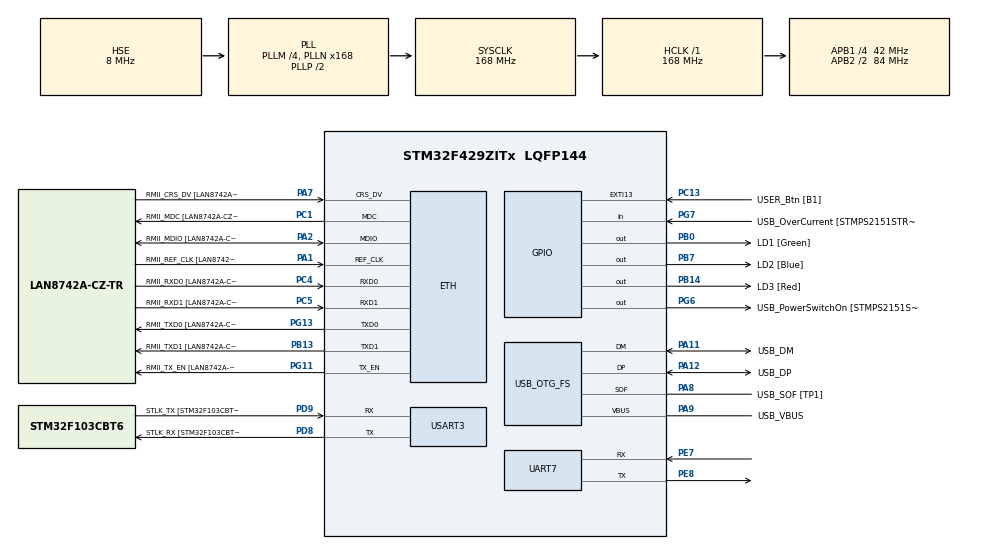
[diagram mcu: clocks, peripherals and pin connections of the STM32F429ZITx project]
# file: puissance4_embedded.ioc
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Mcu.Family=STM32F4
FREERTOS.Queues01=queue_user_to_app,16,data_msg,0,Dynamic,NULL,NULL;queue_app_to_display,16,data_msg,0,Dynamic,NULL,NULL
RCC.CortexFreq_Value=168000000
PG6.Signal=GPIO_Output
PB14.GPIO_Label=LD3 [Red]
PG6.GPIO_Label=USB_PowerSwitchOn [STMPS2151STR_EN]
PA14.GPIO_Label=TCK
RCC.SYSCLKSourceVirtual=RCC_SYSCLKSOURCE_PLLCLK
PA11.Mode=Device_Only
PB0.GPIO_Label=LD1 [Green]
PC14/OSC32_IN.Mode=LSE-External-Oscillator
PC5.Mode=RMII
PC13.GPIO_Label=USER_Btn [B1]
PB13.GPIO_Label=RMII_TXD1 [LAN8742A-CZ-TR_TXD1]
PB13.Signal=ETH_TXD1
PG13.Signal=ETH_TXD0
PD9.Mode=Asynchronous
PG11.Signal=ETH_TX_EN
RCC.SYSCLKSource=RCC_SYSCLKSOURCE_PLLCLK
ProjectManager.StackSize=0x400
VP_FREERTOS_VS_CMSIS_V2.Mode=CMSIS_V2
PA12.Signal=USB_OTG_FS_DP
ETH.PHY_Value=0
PH0/OSC_IN.Mode=HSE-External-Clock-Source
RCC.HCLKFreq_Value=168000000
RCC.APB2TimFreq_Value=168000000
PH1/OSC_OUT.Signal=RCC_OSC_OUT
PD8.Signal=USART3_TX
RCC.AHBFreq_Value=168000000
RCC.HSE_VALUE=8000000
RCC.PLLMUL=RCC_PLL_MUL9
PC4.GPIO_Label=RMII_RXD0 [LAN8742A-CZ-TR_RXD0]
PA14.Mode=Serial_Wire
VP_SYS_VS_tim1.Mode=TIM1
PA10.GPIO_Label=USB_ID
PB7.Signal=GPIO_Output
PA8.Signal=USB_OTG_FS_SOF
PG13.Mode=RMII
ETH.PHY_Name=LAN8742A_PHY_ADDRESS
PH1/OSC_OUT.Mode=HSE-External-Clock-Source
PB7.GPIO_Label=LD2 [Blue]
Mcu.Package=LQFP144
NVIC.TimeBase=TIM1_UP_TIM10_IRQn
PC14/OSC32_IN.Signal=RCC_OSC32_IN
PA2.GPIO_Label=RMII_MDIO [LAN8742A-CZ-TR_MDIO]
NVIC.TimeBaseIP=TIM1
PA10.Signal=USB_OTG_FS_ID
USB_OTG_FS.VirtualMode=Device_Only
RCC.APB2CLKDivider=RCC_HCLK_DIV2
RCC.APB1TimFreq_Value=84000000
PG11.GPIO_Label=RMII_TX_EN [LAN8742A-CZ-TR_TXEN]
PC5.Signal=ETH_RXD1
PB13.Mode=RMII
PE7.Signal=UART7_RX
PC4.Mode=RMII
FREERTOS.Tasks01=user_command,24,128,user_button,As weak,NULL,Dynamic,NULL,NULL;app_puissance4,24,128,application,As external,NULL,Dynamic,NULL,NULL;display_board,24,128,show_board,As external,NULL,Dynamic,NULL,NULL;task_timer,24,128,timers,As external,NULL,Dynamic,NULL,NULL;task_serial,24,128,serial,As external,NULL,Dynamic,NULL,NULL
PA7.Mode=RMII
PG7.Signal=GPIO_Input
PD9.GPIO_Label=STLK_TX [STM32F103CBT6_PA2]
PC13.Signal=GPXTI13
PA9.GPIO_Label=USB_VBUS
PC4.Signal=ETH_RXD0
PA11.GPIO_Label=USB_DM
PD9.Signal=USART3_RX
UART7.VirtualMode=Asynchronous
RCC.APB1CLKDivider=RCC_HCLK_DIV4
PG13.GPIO_Label=RMII_TXD0 [LAN8742A-CZ-TR_TXD0]
ETH.PhyAddress=0
PA12.GPIO_Label=USB_DP
PD8.GPIO_Label=STLK_RX [STM32F103CBT6_PA3]
PE8.Mode=Asynchronous
PA13.Signal=SYS_JTMS-SWDIO
PA9.Mode=Activate_VBUS
PA8.GPIO_Label=USB_SOF [TP1]
ProjectManager.TargetToolchain=TrueSTUDIO
PA9.Signal=USB_OTG_FS_VBUS
RCC.USBFreq_Value=48000000
PD8.Mode=Asynchronous
PA1.Signal=ETH_REF_CLK
PB14.Signal=GPIO_Output
board=NUCLEO-F429ZI
RCC.VCOOutputFreq_Value=336000000
PH0/OSC_IN.Signal=RCC_OSC_IN
RCC.APB2Freq_Value=84000000
PA1.Mode=RMII
RCC.PRESCALERUSB=RCC_USBCLKSOURCE_PLL_DIV1_5
PE8.Signal=UART7_TX
PG7.GPIO_Label=USB_OverCurrent [STMPS2151STR_FAULT]
PA1.GPIO_Label=RMII_REF_CLK [LAN8742A-CZ-TR_REFCLK0]
PC1.GPIO_Label=RMII_MDC [LAN8742A-CZ-TR_MDC]
PA13.Mode=Serial_Wire
Mcu.Name=STM32F429ZITx
PA2.Signal=ETH_MDIO
PA13.GPIO_Label=TMS
RCC.APB2TimCLKDivider=2
RCC.48MHZClocksFreq_Value=48000000
RCC.SYSCLKFreq_VALUE=168000000
PE7.Mode=Asynchronous
ETH.MediaInterface=ETH_MEDIA_INTERFACE_RMII
PA7.GPIO_Label=RMII_CRS_DV [LAN8742A-CZ-TR_CRS_DV]
PA12.Mode=Device_Only
PC5.GPIO_Label=RMII_RXD1 [LAN8742A-CZ-TR_RXD1]
USART3.VirtualMode=VM_ASYNC
PC15/OSC32_OUT.Mode=LSE-External-Oscillator
PG11.Mode=RMII
PA11.Signal=USB_OTG_FS_DM
PA14.Signal=SYS_JTCK-SWCLK
ProjectManager.HeapSize=0x200
NVIC.TIM1_UP_TIM10_IRQn=true\:0\:0\:false\:false\:true\:false\:false\:true
RCC.HSI_VALUE=16000000
PH0/OSC_IN.GPIO_Label=MCO [STM32F103CBT6_PA8]
FREERTOS.Mutexes01=timer_mutex,Dynamic,NULL
RCC.PLLQ=7
NVIC.PriorityGroup=NVIC_PRIORITYGROUP_4
RCC.PLLM=4
RCC.PLLN=168
PA2.Mode=RMII
PC15/OSC32_OUT.Signal=RCC_OSC32_OUT
PA8.Mode=Activate_SOF_FS
RCC.APB1Freq_Value=42000000
PB0.Signal=GPIO_Output
PC1.Signal=ETH_MDC
PC1.Mode=RMII
PA7.Signal=ETH_CRS_DV

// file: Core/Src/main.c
/* USER CODE BEGIN Header */
/**
 ******************************************************************************
 * @file           : main.c
 * @brief          : Main program body
 ******************************************************************************
 * @attention
 *
 * <h2><center>&copy; Copyright (c) 2020 STMicroelectronics.
 * All rights reserved.</center></h2>
 *
 * This software component is licensed by ST under Ultimate Liberty license
 * SLA0044, the "License"; You may not use this file except in compliance with
 * the License. You may obtain a copy of the License at:
 *                             www.st.com/SLA0044
 *
 ******************************************************************************
 */
/* USER CODE END Header */
#include "main.h"
#include "cmsis_os.h"

/* USER CODE BEGIN Includes */
#include "game.h"
#include "leds_control.h"
/* USER CODE END Includes */

ETH_HandleTypeDef heth;

UART_HandleTypeDef huart7;
UART_HandleTypeDef huart3;

PCD_HandleTypeDef hpcd_USB_OTG_FS;

/* Definitions for user_command */
osThreadId_t user_commandHandle;
const osThreadAttr_t user_command_attributes = {
  .name = "user_command",
  .priority = (osPriority_t) osPriorityNormal,
  .stack_size = 128 * 4
};
/* Definitions for app_puissance4 */
osThreadId_t app_puissance4Handle;
const osThreadAttr_t app_puissance4_attributes = {
  .name = "app_puissance4",
  .priority = (osPriority_t) osPriorityNormal,
  .stack_size = 128 * 4
};
/* Definitions for display_board */
osThreadId_t display_boardHandle;
const osThreadAttr_t display_board_attributes = {
  .name = "display_board",
  .priority = (osPriority_t) osPriorityNormal,
  .stack_size = 128 * 4
};
/* Definitions for task_timer */
osThreadId_t task_timerHandle;
const osThreadAttr_t task_timer_attributes = {
  .name = "task_timer",
  .priority = (osPriority_t) osPriorityNormal,
  .stack_size = 128 * 4
};
/* Definitions for task_serial */
osThreadId_t task_serialHandle;
const osThreadAttr_t task_serial_attributes = {
  .name = "task_serial",
  .priority = (osPriority_t) osPriorityNormal,
  .stack_size = 128 * 4
};
/* Definitions for queue_user_to_app */
osMessageQueueId_t queue_user_to_appHandle;
const osMessageQueueAttr_t queue_user_to_app_attributes = {
  .name = "queue_user_to_app"
};
/* Definitions for queue_app_to_display */
osMessageQueueId_t queue_app_to_displayHandle;
const osMessageQueueAttr_t queue_app_to_display_attributes = {
  .name = "queue_app_to_display"
};
/* Definitions for timer_mutex */
//osMutexId_t timer_mutexHandle;
//const osMutexAttr_t timer_mutex_attributes = {
//  .name = "timer_mutex"
//};
/* USER CODE BEGIN PV */
/* Definitions for queue_huart_transmit */
osMessageQueueId_t queue_huart_transmitHandle;
const osMessageQueueAttr_t queue_huart_transmit_attributes = {
		.name = "queue_user_transmit"
};
/* Definitions for queue_huart_receive */
osMessageQueueId_t queue_huart_receiveHandle;
const osMessageQueueAttr_t queue_huart_receive_attributes = {
		.name = "queue_huart_receive"
};
/* USER CODE END PV */

void SystemClock_Config(void);
static void MX_GPIO_Init(void);
static void MX_ETH_Init(void);
static void MX_USART3_UART_Init(void);
static void MX_USB_OTG_FS_PCD_Init(void);
static void MX_UART7_Init(void);
void user_button(void *argument);
extern void application(void *argument);
extern void show_board(void *argument);
extern void timers(void *argument);
extern void serial(void *argument);

int main(void)
{

  /* MCU Configuration--------------------------------------------------------*/

  /* Reset of all peripherals, Initializes the Flash interface and the Systick. */
  HAL_Init();

  /* Configure the system clock */
  SystemClock_Config();

  /* Initialize all configured peripherals */
  MX_GPIO_Init();
  //MX_ETH_Init();
  MX_USART3_UART_Init();
  //MX_USB_OTG_FS_PCD_Init();
  MX_UART7_Init();

  /* Init scheduler */
  osKernelInitialize();
  /* Create the mutex(es) */
  /* creation of timer_mutex */
  //timer_mutexHandle = osMutexNew(&timer_mutex_attributes);

  /* Create the queue(s) */
  /* creation of queue_user_to_app */
  queue_user_to_appHandle = osMessageQueueNew (16, sizeof(data_msg), &queue_user_to_app_attributes);

  /* creation of queue_app_to_display */
  queue_app_to_displayHandle = osMessageQueueNew (16, sizeof(data_msg), &queue_app_to_display_attributes);

  /* USER CODE BEGIN RTOS_QUEUES */
	/* creation of queue_huart_transmit */
	queue_huart_transmitHandle = osMessageQueueNew (16, SIZE_OF_LED_COMMAND_BUFFER, &queue_huart_transmit_attributes);

	/* creation of queue_huart_receive */
	queue_huart_receiveHandle = osMessageQueueNew (16, SIZE_OF_PLAYER_COMMAND_BUFFER, &queue_huart_receive_attributes);
  /* USER CODE END RTOS_QUEUES */

  /* Create the thread(s) */
  /* creation of user_command */
  user_commandHandle = osThreadNew(user_button, NULL, &user_command_attributes);

  /* creation of app_puissance4 */
  app_puissance4Handle = osThreadNew(application, NULL, &app_puissance4_attributes);

  /* creation of display_board */
  display_boardHandle = osThreadNew(show_board, NULL, &display_board_attributes);

  /* creation of task_timer */
  task_timerHandle = osThreadNew(timers, NULL, &task_timer_attributes);

  /* creation of task_serial */
  task_serialHandle = osThreadNew(serial, NULL, &task_serial_attributes);

  /* Start scheduler */
  osKernelStart();

  /* We should never get here as control is now taken by the scheduler */
  /* Infinite loop */
	while (1)
	{

	}
}

void SystemClock_Config(void)
{
  RCC_OscInitTypeDef RCC_OscInitStruct = {0};
  RCC_ClkInitTypeDef RCC_ClkInitStruct = {0};

  /** Configure the main internal regulator output voltage
  */
  __HAL_RCC_PWR_CLK_ENABLE();
  __HAL_PWR_VOLTAGESCALING_CONFIG(PWR_REGULATOR_VOLTAGE_SCALE1);
  /** Initializes the RCC Oscillators according to the specified parameters
  * in the RCC_OscInitTypeDef structure.
  */
  RCC_OscInitStruct.OscillatorType = RCC_OSCILLATORTYPE_HSE;
  RCC_OscInitStruct.HSEState = RCC_HSE_BYPASS;
  RCC_OscInitStruct.PLL.PLLState = RCC_PLL_ON;
  RCC_OscInitStruct.PLL.PLLSource = RCC_PLLSOURCE_HSE;
  RCC_OscInitStruct.PLL.PLLM = 4;
  RCC_OscInitStruct.PLL.PLLN = 168;
  RCC_OscInitStruct.PLL.PLLP = RCC_PLLP_DIV2;
  RCC_OscInitStruct.PLL.PLLQ = 7;
  if (HAL_RCC_OscConfig(&RCC_OscInitStruct) != HAL_OK)
  {
    Error_Handler();
  }
  /** Initializes the CPU, AHB and APB buses clocks
  */
  RCC_ClkInitStruct.ClockType = RCC_CLOCKTYPE_HCLK|RCC_CLOCKTYPE_SYSCLK
                              |RCC_CLOCKTYPE_PCLK1|RCC_CLOCKTYPE_PCLK2;
  RCC_ClkInitStruct.SYSCLKSource = RCC_SYSCLKSOURCE_PLLCLK;
  RCC_ClkInitStruct.AHBCLKDivider = RCC_SYSCLK_DIV1;
  RCC_ClkInitStruct.APB1CLKDivider = RCC_HCLK_DIV4;
  RCC_ClkInitStruct.APB2CLKDivider = RCC_HCLK_DIV2;

  if (HAL_RCC_ClockConfig(&RCC_ClkInitStruct, FLASH_LATENCY_5) != HAL_OK)
  {
    Error_Handler();
  }
}

static void MX_ETH_Init(void)
{

  heth.Instance = ETH;
  heth.Init.AutoNegotiation = ETH_AUTONEGOTIATION_ENABLE;
  heth.Init.PhyAddress = LAN8742A_PHY_ADDRESS;
  heth.Init.MACAddr[0] =   0x00;
  heth.Init.MACAddr[1] =   0x80;
  heth.Init.MACAddr[2] =   0xE1;
  heth.Init.MACAddr[3] =   0x00;
  heth.Init.MACAddr[4] =   0x00;
  heth.Init.MACAddr[5] =   0x00;
  heth.Init.RxMode = ETH_RXPOLLING_MODE;
  heth.Init.ChecksumMode = ETH_CHECKSUM_BY_HARDWARE;
  heth.Init.MediaInterface = ETH_MEDIA_INTERFACE_RMII;

  if (HAL_ETH_Init(&heth) != HAL_OK)
  {
    Error_Handler();
  }

}

static void MX_UART7_Init(void)
{

  huart7.Instance = UART7;
  huart7.Init.BaudRate = 115200;
  huart7.Init.WordLength = UART_WORDLENGTH_8B;
  huart7.Init.StopBits = UART_STOPBITS_1;
  huart7.Init.Parity = UART_PARITY_NONE;
  huart7.Init.Mode = UART_MODE_TX_RX;
  huart7.Init.HwFlowCtl = UART_HWCONTROL_NONE;
  huart7.Init.OverSampling = UART_OVERSAMPLING_16;
  if (HAL_UART_Init(&huart7) != HAL_OK)
  {
    Error_Handler();
  }

}

static void MX_USART3_UART_Init(void)
{

  huart3.Instance = USART3;
  huart3.Init.BaudRate = 115200;
  huart3.Init.WordLength = UART_WORDLENGTH_8B;
  huart3.Init.StopBits = UART_STOPBITS_1;
  huart3.Init.Parity = UART_PARITY_NONE;
  huart3.Init.Mode = UART_MODE_TX_RX;
  huart3.Init.HwFlowCtl = UART_HWCONTROL_NONE;
  huart3.Init.OverSampling = UART_OVERSAMPLING_16;
  if (HAL_UART_Init(&huart3) != HAL_OK)
  {
    Error_Handler();
  }

}

static void MX_USB_OTG_FS_PCD_Init(void)
{

  hpcd_USB_OTG_FS.Instance = USB_OTG_FS;
  hpcd_USB_OTG_FS.Init.dev_endpoints = 4;
  hpcd_USB_OTG_FS.Init.speed = PCD_SPEED_FULL;
  hpcd_USB_OTG_FS.Init.dma_enable = DISABLE;
  hpcd_USB_OTG_FS.Init.phy_itface = PCD_PHY_EMBEDDED;
  hpcd_USB_OTG_FS.Init.Sof_enable = ENABLE;
  hpcd_USB_OTG_FS.Init.low_power_enable = DISABLE;
  hpcd_USB_OTG_FS.Init.lpm_enable = DISABLE;
  hpcd_USB_OTG_FS.Init.vbus_sensing_enable = ENABLE;
  hpcd_USB_OTG_FS.Init.use_dedicated_ep1 = DISABLE;
  if (HAL_PCD_Init(&hpcd_USB_OTG_FS) != HAL_OK)
  {
    Error_Handler();
  }

}

static void MX_GPIO_Init(void)
{
  GPIO_InitTypeDef GPIO_InitStruct = {0};

  /* GPIO Ports Clock Enable */
  __HAL_RCC_GPIOC_CLK_ENABLE();
  __HAL_RCC_GPIOH_CLK_ENABLE();
  __HAL_RCC_GPIOA_CLK_ENABLE();
  __HAL_RCC_GPIOB_CLK_ENABLE();
  __HAL_RCC_GPIOE_CLK_ENABLE();
  __HAL_RCC_GPIOD_CLK_ENABLE();
  __HAL_RCC_GPIOG_CLK_ENABLE();

  /*Configure GPIO pin Output Level */
  HAL_GPIO_WritePin(GPIOB, LD1_Pin|LD3_Pin|LD2_Pin, GPIO_PIN_RESET);

  /*Configure GPIO pin Output Level */
  HAL_GPIO_WritePin(USB_PowerSwitchOn_GPIO_Port, USB_PowerSwitchOn_Pin, GPIO_PIN_RESET);

  /*Configure GPIO pin : USER_Btn_Pin */
  GPIO_InitStruct.Pin = USER_Btn_Pin;
  GPIO_InitStruct.Mode = GPIO_MODE_IT_RISING;
  GPIO_InitStruct.Pull = GPIO_NOPULL;
  HAL_GPIO_Init(USER_Btn_GPIO_Port, &GPIO_InitStruct);

  /*Configure GPIO pins : LD1_Pin LD3_Pin LD2_Pin */
  GPIO_InitStruct.Pin = LD1_Pin|LD3_Pin|LD2_Pin;
  GPIO_InitStruct.Mode = GPIO_MODE_OUTPUT_PP;
  GPIO_InitStruct.Pull = GPIO_NOPULL;
  GPIO_InitStruct.Speed = GPIO_SPEED_FREQ_LOW;
  HAL_GPIO_Init(GPIOB, &GPIO_InitStruct);

  /*Configure GPIO pin : USB_PowerSwitchOn_Pin */
  GPIO_InitStruct.Pin = USB_PowerSwitchOn_Pin;
  GPIO_InitStruct.Mode = GPIO_MODE_OUTPUT_PP;
  GPIO_InitStruct.Pull = GPIO_NOPULL;
  GPIO_InitStruct.Speed = GPIO_SPEED_FREQ_LOW;
  HAL_GPIO_Init(USB_PowerSwitchOn_GPIO_Port, &GPIO_InitStruct);

  /*Configure GPIO pin : USB_OverCurrent_Pin */
  GPIO_InitStruct.Pin = USB_OverCurrent_Pin;
  GPIO_InitStruct.Mode = GPIO_MODE_INPUT;
  GPIO_InitStruct.Pull = GPIO_NOPULL;
  HAL_GPIO_Init(USB_OverCurrent_GPIO_Port, &GPIO_InitStruct);

}

__weak void user_button(void *argument)
{
	for(;;)
	{
		osDelay(1);
	}
}

void HAL_TIM_PeriodElapsedCallback(TIM_HandleTypeDef *htim)
{
  if (htim->Instance == TIM1) {
    HAL_IncTick();
  }
}

void Error_Handler(void)
{
}

/************************ (C) COPYRIGHT STMicroelectronics *****END OF FILE****/
